# R9A09G057H register map
Vendor: Renesas Electronics; File version: 1.0
Registers are 32-bit, read-write, no defined reset value unless marked. A register's access mark holds for its fields unless they carry their own. Offsets are from the block's base; [hi:lo] are bit positions; {n}, {i} and the like mark numbered series.

## R_I3C_B0 — IO define file for i3c.
Base 0x12400000
0x00 PRTS
  [0] PRTMD
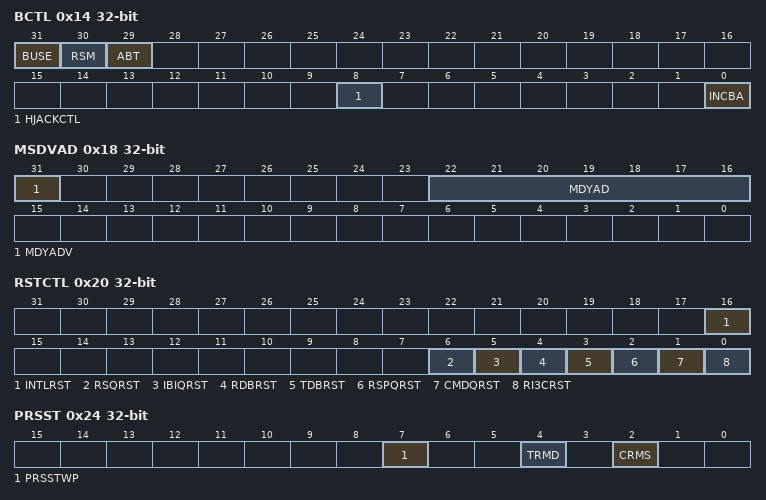
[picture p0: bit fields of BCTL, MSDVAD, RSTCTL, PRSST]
0x14 BCTL
  [31] BUSE, [30] RSM, [29] ABT, [8] HJACKCTL, [0] INCBA
0x18 MSDVAD
  [31] MDYADV, [22:16] MDYAD
0x20 RSTCTL
  [16] INTLRST, [6] RSQRST, [5] IBIQRST, [4] RDBRST, [3] TDBRST, [2] RSPQRST, [1] CMDQRST, [0] RI3CRST
0x24 PRSST
  [7] PRSSTWP wo, [4] TRMD ro, [2] CRMS
0x30 INST
  [10] INEF
0x34 INSTE
  [10] INEE
0x38 INIE
  [10] INEIE
0x3C INSTFC wo
  [10] INEFC
0x44 DVCT ro
  [23:19] IDX
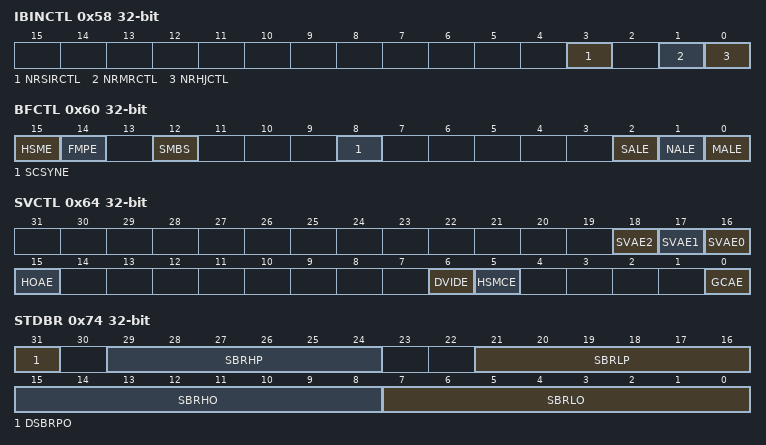
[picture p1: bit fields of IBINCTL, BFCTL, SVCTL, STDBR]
0x58 IBINCTL
  [3] NRSIRCTL, [1] NRMRCTL, [0] NRHJCTL
0x60 BFCTL
  [15] HSME, [14] FMPE, [12] SMBS, [8] SCSYNE, [2] SALE, [1] NALE, [0] MALE
0x64 SVCTL
  [18] SVAE2, [17] SVAE1, [16] SVAE0, [15] HOAE, [6] DVIDE, [5] HSMCE, [0] GCAE
0x70 REFCKCTL
  [2:0] IREFCKS
0x74 STDBR
  [31] DSBRPO, [29:24] SBRHP, [21:16] SBRLP, [15:8] SBRHO, [7:0] SBRLO
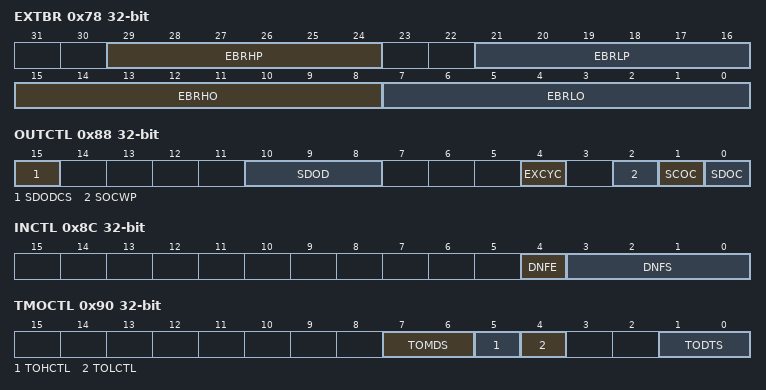
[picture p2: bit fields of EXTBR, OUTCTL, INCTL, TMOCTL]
0x78 EXTBR
  [29:24] EBRHP, [21:16] EBRLP, [15:8] EBRHO, [7:0] EBRLO
0x7C BFRECDT
  [8:0] FRECYC
0x80 BAVLCDT
  [8:0] AVLCYC
0x84 BIDLCDT
  [17:0] IDLCYC
0x88 OUTCTL
  [15] SDODCS, [10:8] SDOD, [4] EXCYC, [2] SOCWP wo, [1] SCOC, [0] SDOC
0x8C INCTL
  [4] DNFE, [3:0] DNFS
0x90 TMOCTL
  [7:6] TOMDS, [5] TOHCTL, [4] TOLCTL, [1:0] TODTS
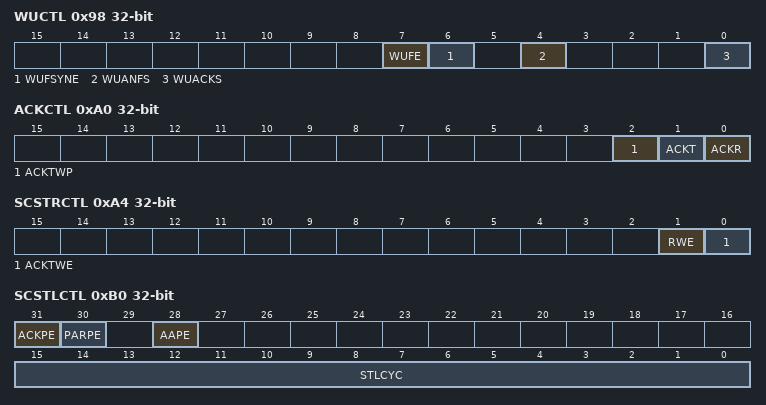
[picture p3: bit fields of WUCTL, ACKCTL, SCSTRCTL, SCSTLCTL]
0x98 WUCTL
  [7] WUFE, [6] WUFSYNE, [4] WUANFS, [0] WUACKS
0xA0 ACKCTL
  [2] ACKTWP wo, [1] ACKT, [0] ACKR ro
0xA4 SCSTRCTL
  [1] RWE, [0] ACKTWE
0xB0 SCSTLCTL
  [31] ACKPE, [30] PARPE, [28] AAPE, [15:0] STLCYC
0xC0 SVTDLG0
  [31:16] STDLG
0x120 STCTL
  [0] STOE
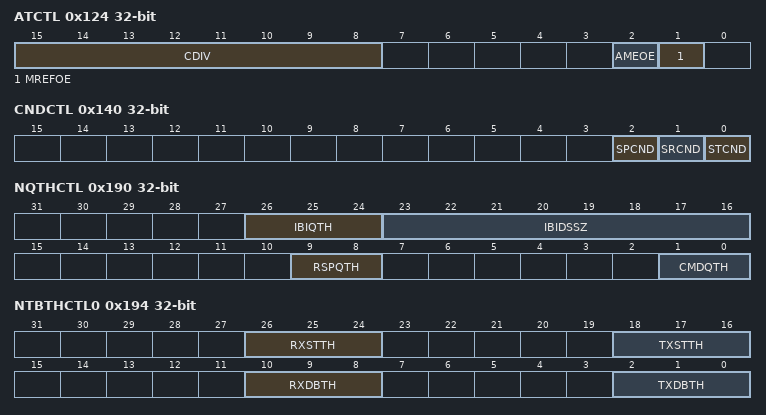
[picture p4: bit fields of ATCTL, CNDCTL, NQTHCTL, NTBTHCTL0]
0x124 ATCTL
  [15:8] CDIV, [2] AMEOE, [1] MREFOE
0x128 ATTRG wo
  [0] ATSTRG
0x12C ATCCNTE
  [0] ATCE
0x140 CNDCTL
  [2] SPCND, [1] SRCND, [0] STCND
0x150 NCMDQP wo
0x154 NRSPQP ro
0x158 NTDTBP0
0x158 NTDTBP0_BY 8-bit
  [7:0] NTDTBP0
0x17C NIBIQP
0x180 NRSQP ro
0x190 NQTHCTL
  [26:24] IBIQTH, [23:16] IBIDSSZ, [9:8] RSPQTH, [1:0] CMDQTH
0x194 NTBTHCTL0
  [26:24] RXSTTH, [18:16] TXSTTH, [10:8] RXDBTH, [2:0] TXDBTH
0x1C0 NRQTHCTL
  [0] RSQTH
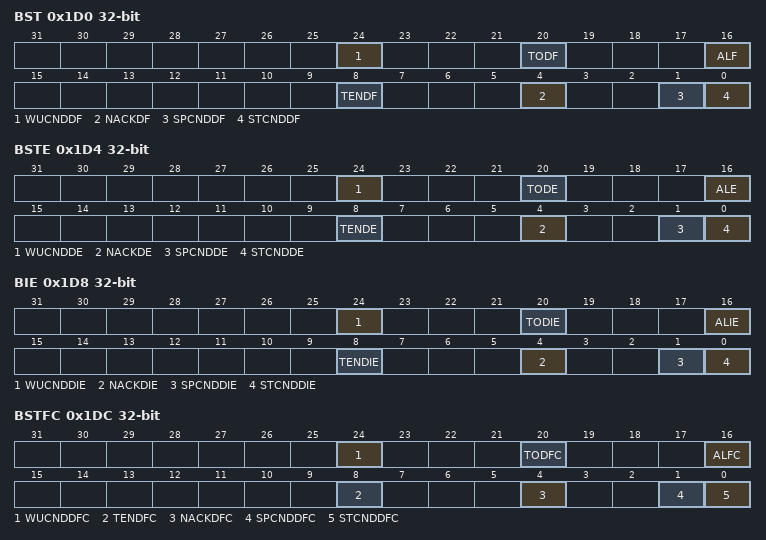
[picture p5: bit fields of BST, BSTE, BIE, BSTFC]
0x1D0 BST
  [24] WUCNDDF, [20] TODF, [16] ALF, [8] TENDF, [4] NACKDF, [1] SPCNDDF, [0] STCNDDF
0x1D4 BSTE
  [24] WUCNDDE, [20] TODE, [16] ALE, [8] TENDE, [4] NACKDE, [1] SPCNDDE, [0] STCNDDE
0x1D8 BIE
  [24] WUCNDDIE, [20] TODIE, [16] ALIE, [8] TENDIE, [4] NACKDIE, [1] SPCNDDIE, [0] STCNDDIE
0x1DC BSTFC
  [24] WUCNDDFC wo, [20] TODFC wo, [16] ALFC wo, [8] TENDFC wo, [4] NACKDFC wo, [1] SPCNDDFC wo, [0] STCNDDFC wo
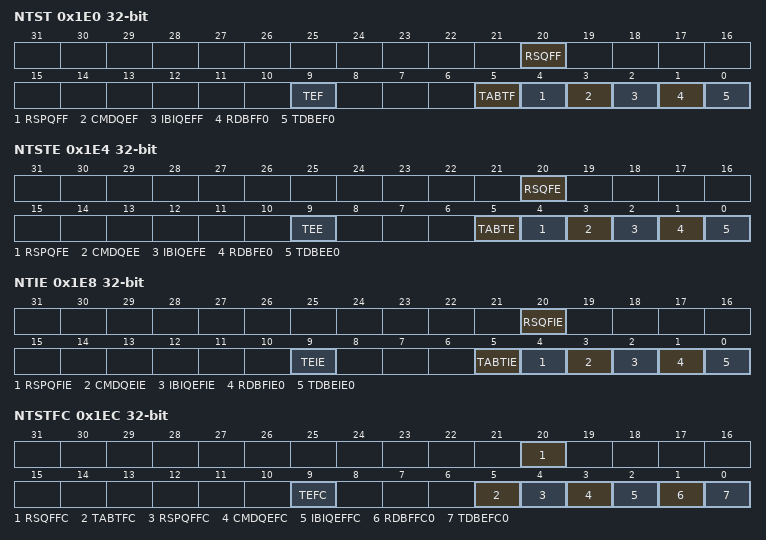
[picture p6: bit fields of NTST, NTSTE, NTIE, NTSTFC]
0x1E0 NTST
  [20] RSQFF, [9] TEF, [5] TABTF, [4] RSPQFF, [3] CMDQEF, [2] IBIQEFF, [1] RDBFF0, [0] TDBEF0
0x1E4 NTSTE
  [20] RSQFE, [9] TEE, [5] TABTE, [4] RSPQFE, [3] CMDQEE, [2] IBIQEFE, [1] RDBFE0, [0] TDBEE0
0x1E8 NTIE
  [20] RSQFIE, [9] TEIE, [5] TABTIE, [4] RSPQFIE, [3] CMDQEIE, [2] IBIQEFIE, [1] RDBFIE0, [0] TDBEIE0
0x1EC NTSTFC wo
  [20] RSQFFC, [9] TEFC, [5] TABTFC, [4] RSPQFFC, [3] CMDQEFC, [2] IBIQEFFC, [1] RDBFFC0, [0] TDBEFC0
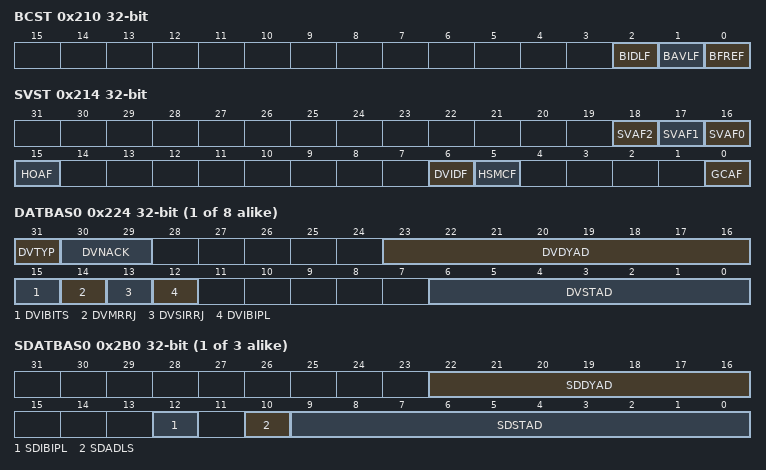
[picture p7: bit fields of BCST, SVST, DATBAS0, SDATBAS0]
0x210 BCST ro
  [2] BIDLF, [1] BAVLF, [0] BFREF
0x214 SVST
  [18] SVAF2, [17] SVAF1, [16] SVAF0, [15] HOAF, [6] DVIDF, [5] HSMCF, [0] GCAF
0x218 WUST ro
  [0] WUASYNF
0x21C MRCCPT ro
{0x224+4i} DATBAS{i} (i=0..7)
  [31] DVTYP, [30:29] DVNACK, [23:16] DVDYAD, [15] DVIBITS, [14] DVMRRJ, [13] DVSIRRJ, [12] DVIBIPL, [6:0] DVSTAD
{0x2B0+4i} SDATBAS{i} (i=0..2)
  [22:16] SDDYAD, [12] SDIBIPL, [10] SDADLS, [9:0] SDSTAD
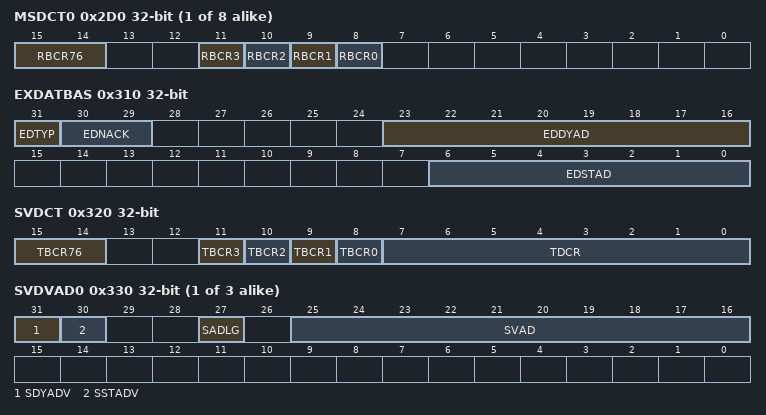
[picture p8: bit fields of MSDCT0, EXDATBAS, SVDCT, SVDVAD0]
{0x2D0+4i} MSDCT{i} (i=0..7)
  [15:14] RBCR76, [n+8] RBCR{n} (n=0..3)
0x310 EXDATBAS
  [31] EDTYP, [30:29] EDNACK, [23:16] EDDYAD, [6:0] EDSTAD
0x320 SVDCT
  [15:14] TBCR76, [n+8] TBCR{n} (n=0..3), [7:0] TDCR
0x324 SDCTPIDL
0x328 SDCTPIDH
{0x330+4i} SVDVAD{i} (i=0..2)
  [31] SDYADV ro, [30] SSTADV ro, [27] SADLG ro, [25:16] SVAD ro
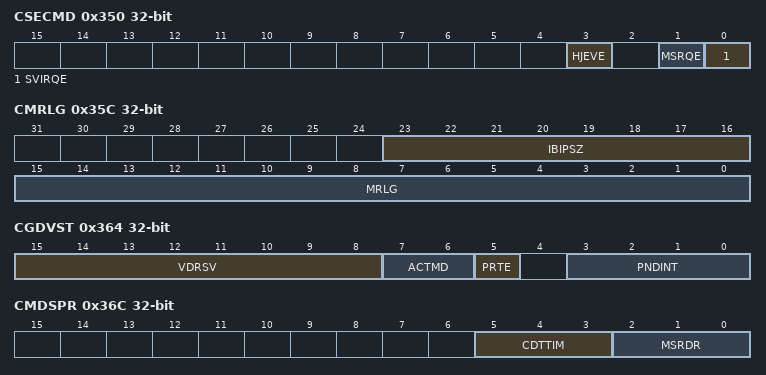
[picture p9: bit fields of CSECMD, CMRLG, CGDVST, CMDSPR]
0x350 CSECMD
  [3] HJEVE, [1] MSRQE, [0] SVIRQE
0x354 CEACTST
  [3:0] ACTST
0x358 CMWLG
  [15:0] MWLG
0x35C CMRLG
  [23:16] IBIPSZ, [15:0] MRLG
0x360 CETSTMD ro
  [7:0] TSTMD
0x364 CGDVST
  [15:8] VDRSV, [7:6] ACTMD, [5] PRTE, [3:0] PNDINT
0x368 CMDSPW
  [2:0] MSWDR
0x36C CMDSPR
  [5:3] CDTTIM, [2:0] MSRDR
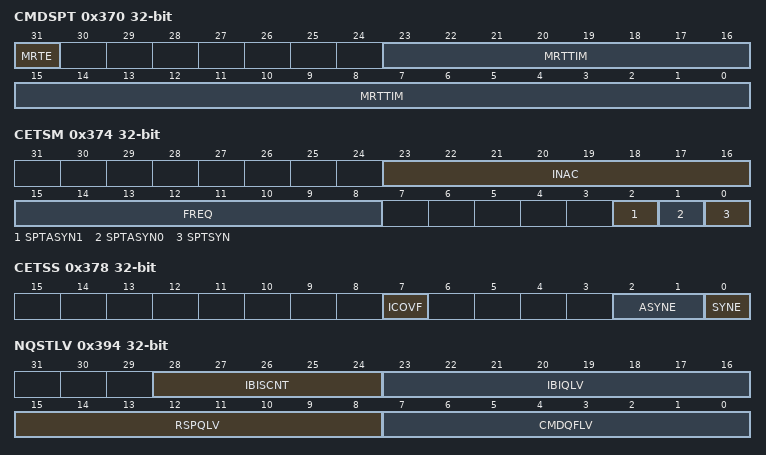
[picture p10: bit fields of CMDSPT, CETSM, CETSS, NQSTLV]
0x370 CMDSPT
  [31] MRTE, [23:0] MRTTIM
0x374 CETSM
  [23:16] INAC, [15:8] FREQ, [2] SPTASYN1, [1] SPTASYN0, [0] SPTSYN
0x378 CETSS
  [7] ICOVF, [2:1] ASYNE, [0] SYNE
0x380 BITCNT ro
  [4:0] BCNT
0x394 NQSTLV ro
  [28:24] IBISCNT, [23:16] IBIQLV, [15:8] RSPQLV, [7:0] CMDQFLV
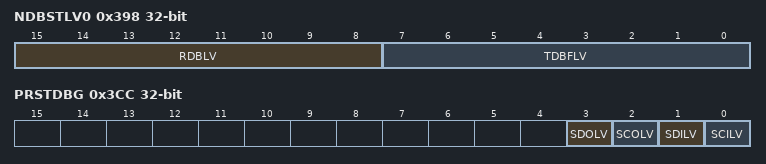
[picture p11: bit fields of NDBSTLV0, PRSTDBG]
0x398 NDBSTLV0 ro
  [15:8] RDBLV, [7:0] TDBFLV
0x3C0 NRSQSTLV ro
  [7:0] RSQLV
0x3CC PRSTDBG ro
  [3] SDOLV, [2] SCOLV, [1] SDILV, [0] SCILV
0x3D0 MSERRCNT ro
  [7:0] M2ECNT
0x3E0 SC1CPT ro
  [15:0] SC1CPT
0x3E4 SC2CPT ro
  [15:0] SC2CPT
